# GD32F20x register map
File version: 1.0
CPU: CM3 r2p1, little endian, no MPU, no FPU, 4 interrupt priority bits
Registers are 32-bit, read-write, reset 0x0 unless marked. A register's access mark holds for its fields unless they carry their own. Offsets are from the block's base; [hi:lo] are bit positions; lines under a group give offsets from that group; {n}, {i} and the like mark numbered series.

## ADC0 — Analog to digital converter
Base 0x40012400
Same registers: ADC1 0x40012800, ADC2 0x40013C00
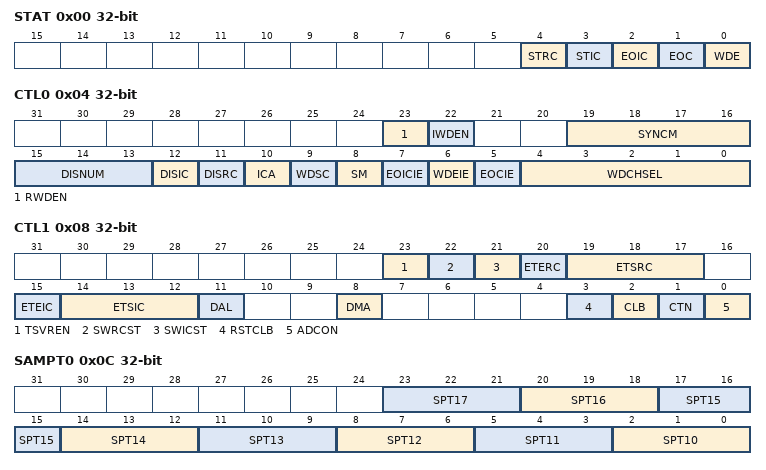
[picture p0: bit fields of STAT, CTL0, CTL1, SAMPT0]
0x00 STAT — status register
  [4] STRC — Start flag of regular channel group
  [3] STIC — Start flag of inserted channel group
  [2] EOIC — End of inserted group conversion flag
  [1] EOC — End of group conversion flag
  [0] WDE — Analog watchdog event flag
0x04 CTL0 — control register 0
  [23] RWDEN — Regular channel analog watchdog enable
  [22] IWDEN — Inserted channel analog watchdog enable
  [19:16] SYNCM — sync mode selection
  [15:13] DISNUM — Number of conversions in discontinuous mode
  [12] DISIC — Discontinuous mode on inserted channels
  [11] DISRC — Discontinuous mode on regular channels
  [10] ICA — Inserted channel group convert automatically
  [9] WDSC — When in scan mode, analog watchdog is effective on a single channel
  [8] SM — Scan mode
  [7] EOICIE — Interrupt enable for EOIC
  [6] WDEIE — Interrupt enable for WDE
  [5] EOCIE — Interrupt enable for EOC
  [4:0] WDCHSEL — Analog watchdog channel select
0x08 CTL1 — control register 1
  [23] TSVREN — Channel 16 and 17 enable of ADC0
  [22] SWRCST — Start on regular channel
  [21] SWICST — Start on inserted channel
  [20] ETERC — External trigger enable for regular channel
  [19:17] ETSRC — External trigger select for regular channel
  [15] ETEIC — External trigger enable for inserted channel
  [14:12] ETSIC — External trigger select for inserted channel
  [11] DAL — Data alignment
  [8] DMA — DMA request enable
  [3] RSTCLB — Reset calibration
  [2] CLB — ADC calibration
  [1] CTN — Continuous mode
  [0] ADCON
0x0C SAMPT0 — Sample time register 0
  [3n-28:3n-30] SPT{n} (n=10..17) — Channel {n} sample time selection
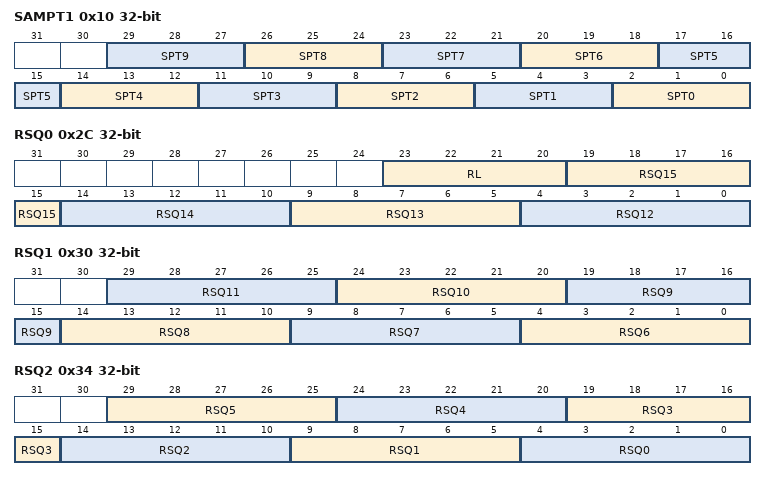
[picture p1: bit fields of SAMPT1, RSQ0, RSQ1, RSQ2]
0x10 SAMPT1 — Sample time register 1
  [3n+2:3n] SPT{n} (n=0..9) — Channel {n} sample time selection
{0x14+4i} IOFF{i} (i=0..3) — Inserted channel data offset register {i}
  [11:0] IOFF — Data offset for inserted channel {i}
0x24 WDHT reset 0xFFF — watchdog higher threshold register
  [11:0] WDHT — Analog watchdog higher threshold
0x28 WDLT — watchdog lower threshold register
  [11:0] WDLT — Analog watchdog lower threshold
0x2C RSQ0 — regular sequence register 0
  [23:20] RL — Regular channel group length
  [5n-56:5n-60] RSQ{n} (n=12..15) — {n+1}th conversion in regular sequence
0x30 RSQ1 — regular sequence register 1
  [5n-26:5n-30] RSQ{n} (n=6..11) — {n+1}th conversion in regular sequence
0x34 RSQ2 — regular sequence register 2
  [29:25] RSQ5 — 6th conversion in regular sequence
  [24:20] RSQ4 — 5th conversion in regular sequence
  [19:15] RSQ3 — 4th conversion in regular sequence
  [14:10] RSQ2 — 3rd conversion in regular sequence
  [9:5] RSQ1 — 2nd conversion in regular sequence
  [4:0] RSQ0 — 1st conversion in regular sequence
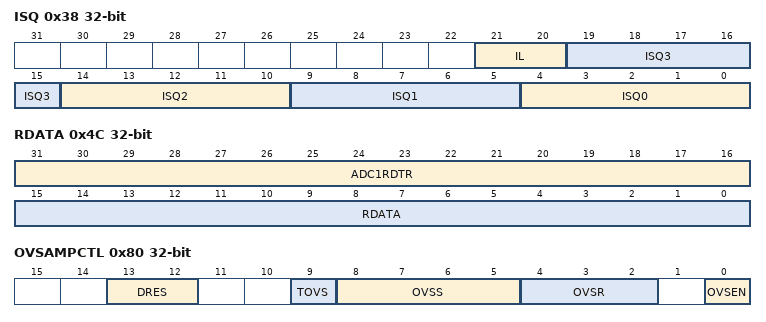
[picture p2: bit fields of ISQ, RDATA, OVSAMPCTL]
0x38 ISQ — Inserted sequence register
  [21:20] IL — Inserted channel group length
  [19:15] ISQ3 — 4th conversion in inserted sequence
  [14:10] ISQ2 — 3rd conversion in inserted sequence
  [9:5] ISQ1 — 2nd conversion in inserted sequence
  [4:0] ISQ0 — 1st conversion in inserted sequence
{0x3C+4i} IDATA{i} ro (i=0..3) — Inserted data register {i}
  [15:0] IDATAn — Inserted number n conversion data
0x4C RDATA ro — regular data register
  [31:16] ADC1RDTR — ADC regular channel data
  [15:0] RDATA — Regular channel data
0x80 OVSAMPCTL — Oversample control register
  [13:12] DRES — ADC resolution
  [9] TOVS — Triggered Oversampling
  [8:5] OVSS — Oversampling shift
  [4:2] OVSR — Oversampling ratio
  [0] OVSEN — Oversampling Enable

## BKP — Backup registers
Base 0x40006C00
{0x4+4i} DATA{i} 16-bit (i=0..9) — Backup data register {i}
  [15:0] DATA — Backup data
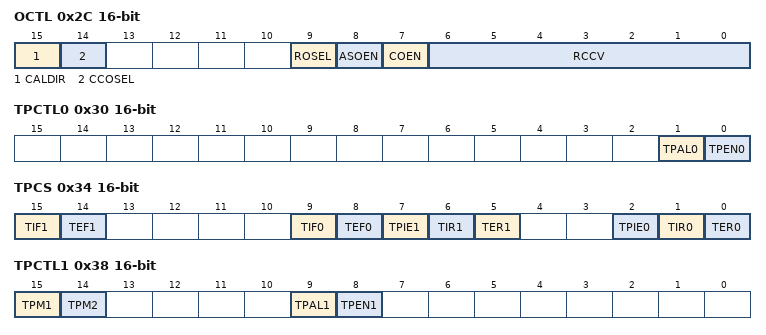
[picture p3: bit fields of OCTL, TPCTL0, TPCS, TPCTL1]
0x2C OCTL 16-bit — RTC signal output control register
  [15] CALDIR — RTC clock calibration direction
  [14] CCOSEL — RTC clock output selection
  [9] ROSEL — RTC output selection
  [8] ASOEN — RTC alarm or second signal output enable
  [7] COEN — RTC clock calibration output enable
  [6:0] RCCV — RTC clock calibration value
0x30 TPCTL0 16-bit — Tamper pin control register 0
  [1] TPAL0 — TAMPER0 pin active level
  [0] TPEN0 — TAMPER0 detection enable
0x34 TPCS 16-bit — Tamper control and status register
  [15] TIF1 — Tamper1 interrupt flag
  [14] TEF1 — Tamper1 event flag
  [9] TIF0 — Tamper0 interrupt flag
  [8] TEF0 — Tamper0 event flag
  [7] TPIE1 — Tamper1interrupt enable
  [6] TIR1 — Tamper1 interrupt reset
  [5] TER1 — Tamper1 event reset
  [2] TPIE0 — Tamper0 interrupt enable
  [1] TIR0 — Tamper0 interrupt reset
  [0] TER0 — Tamper0 event reset
0x38 TPCTL1 16-bit — Tamper pin control register 1
  [15] TPM1 — The first waveform detection enable
  [14] TPM2 — The second waveform detection enable
  [9] TPAL1 — TAMPER1 pin active level
  [8] TPEN1 — TAMPER1 detection enable
{0x18+4i} DATA{i} 16-bit (i=10..41) — Backup data register {i}
  [15:0] DATA — Backup data
